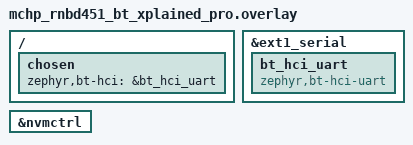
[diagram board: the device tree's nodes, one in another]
/*
 * Copyright (c) 2025-2026 Microchip Technology Inc.
 *
 * SPDX-License-Identifier: Apache-2.0
 */

/ {
	chosen {
		zephyr,bt-hci = &bt_hci_uart;
	};
};

&ext1_serial {
	status = "okay";

	bt_hci_uart: bt_hci_uart {
		compatible = "zephyr,bt-hci-uart";
		status = "okay";
	};
};

&nvmctrl {
	status = "okay";
};
